# MCXN947_cm33_core0 register map
Vendor: nxp.com; File version: 1.0
CPU: CM33 r2p0, little endian, MPU, FPU, VTOR, 3 interrupt priority bits
Registers are 32-bit, read-write, reset 0x0 unless marked. A register's access mark holds for its fields unless they carry their own. Offsets are from the block's base; [hi:lo] are bit positions; {n}, {i} and the like mark numbered series.

## TRNG0
Base 0x4005A000
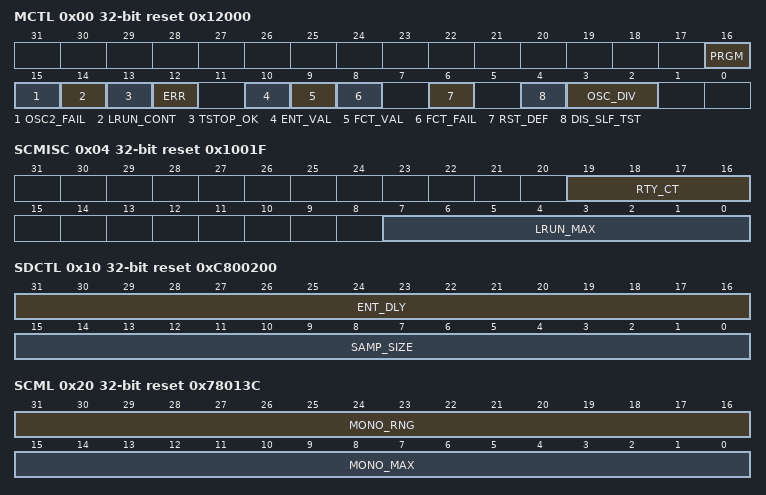
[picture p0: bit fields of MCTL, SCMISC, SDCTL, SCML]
0x00 MCTL reset 0x12000 — Miscellaneous Control Register
  [16] PRGM — Program Mode
    0=DISABLE (TRNG is in Run Mode); 1=ENABLE (TRNG is in Program Mode)
  [15] OSC2_FAIL ro — Oscillator 2 Failure
    0=DISABLE (Oscillator 2 is running.); 1=ENABLE (Oscillator 2 has failed (see OSC2_CTL[OSC_FAILSAFE_LMT]).)
  [14] LRUN_CONT — Long run count continues between entropy generations
    0=DISABLE (The internal test's long run count is restarted for each entropy re-generation.); 1=ENABLE (The count value (of TRNG's internal long_run test), at the start of an entropy generation will continue where it left off at the end of the previous entropy generation.)
  [13] TSTOP_OK ro — TRNG is ok to stop
    0=DISABLE (TRNG is generating entropy and is not ok to stop); 1=ENABLE (TRNG is not generating entropy and is ok to stop)
  [12] ERR write-1-clears — Error Status
    0=DISABLE (No error); 1=ENABLE (Error detected)
  [10] ENT_VAL ro — Entropy Valid
    0=DISABLE (Entropy is not valid); 1=ENABLE (Entropy is valid)
  [9] FCT_VAL ro — Frequency Count Valid
    0=DISABLE (Frequency Count is not valid); 1=ENABLE (Frequency Count is valid)
  [8] FCT_FAIL ro — Frequency Count Fail
  [6] RST_DEF wo — Reset Defaults
    0=DISABLE (No impact.); 1=ENABLE (Writing a 1 to this bit clears various TRNG registers, and bits within registers, to their default state.)
  [4] DIS_SLF_TST wo — Disable Self-Tests
  [3:2] OSC_DIV — Oscillator1 Divide
    0=OSC_DIV_DIV1 (use ring oscillator with no divide); 1=OSC_DIV_DIV2 (use ring oscillator divided-by-2); 2=OSC_DIV_DIV4 (use ring oscillator divided-by-4); 3=OSC_DIV_DIV8 (use ring oscillator divided-by-8)
0x04 SCMISC reset 0x1001F — Statistical Check Miscellaneous Register
  [19:16] RTY_CT — Retry count
  [7:0] LRUN_MAX — Long run max limit
0x10 SDCTL reset 0xC800200 — Seed Control Register
  [31:16] ENT_DLY — Entropy Delay
  [15:0] SAMP_SIZE — Sample Size
0x18 FRQMIN reset 0x1388 (MIN_CNT view) — Frequency Count Minimum Limit Register
  [21:0] FRQ_MIN — Frequency Count Minimum Limit
0x18 OSC2_FRQCNT ro (MIN_CNT view) — Oscillator-2 Frequency Count Register
  [21:0] OSC2_FRQ_CT — Frequency Count
0x1C FRQCNT ro (MAX_CNT view) — Frequency Count Register
  [21:0] FRQ_CT — Frequency Count
0x1C FRQMAX reset 0x61A8 (MAX_CNT view) — Frequency Count Maximum Limit Register
  [21:0] FRQ_MAX — Frequency Counter Maximum Limit
0x20 SCMC ro (SCML_MC view) — Statistical Check Monobit Count Register
  [15:0] MONO_CT — Monobit Count
0x20 SCML reset 0x78013C (SCML_MC view) — Statistical Check Monobit Limit Register
  [31:16] MONO_RNG — Monobit Range
  [15:0] MONO_MAX — Monobit Maximum Limit
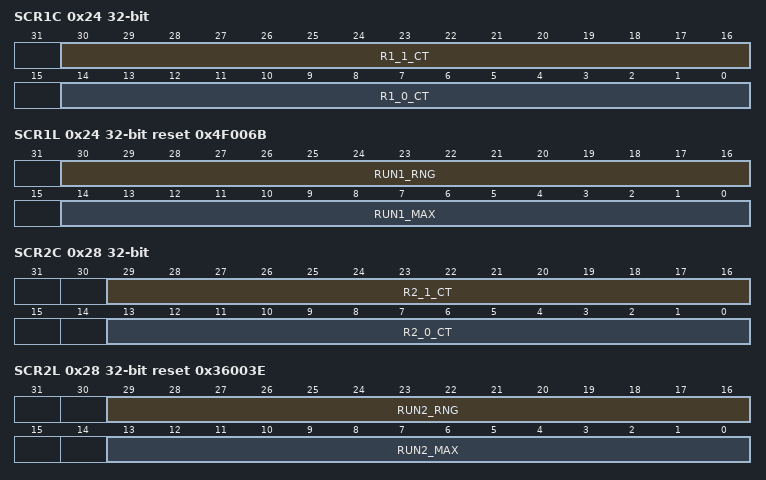
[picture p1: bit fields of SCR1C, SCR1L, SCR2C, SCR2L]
0x24 SCR1C ro (SCR1L_1C view) — Statistical Check Run Length 1 Count Register
  [30:16] R1_1_CT — Runs of One, Length 1 Count
  [14:0] R1_0_CT — Runs of Zero, Length 1 Count
0x24 SCR1L reset 0x4F006B (SCR1L_1C view) — Statistical Check Run Length 1 Limit Register
  [30:16] RUN1_RNG — Run Length 1 Range
  [14:0] RUN1_MAX — Run Length 1 Maximum Limit
0x28 SCR2C ro (SCR2L_2C view) — Statistical Check Run Length 2 Count Register
  [29:16] R2_1_CT — Runs of One, Length 2 Count
  [13:0] R2_0_CT — Runs of Zero, Length 2 Count
0x28 SCR2L reset 0x36003E (SCR2L_2C view) — Statistical Check Run Length 2 Limit Register
  [29:16] RUN2_RNG — Run Length 2 Range
  [13:0] RUN2_MAX — Run Length 2 Maximum Limit
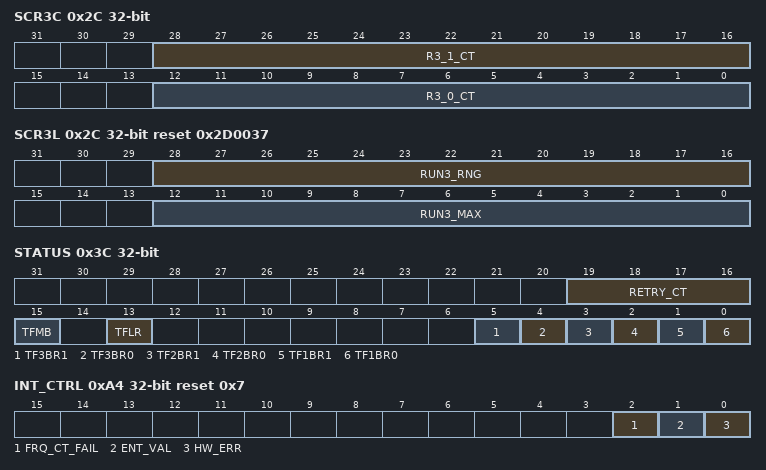
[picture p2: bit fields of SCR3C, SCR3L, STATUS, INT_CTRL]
0x2C SCR3C ro (SCR3L_3C view) — Statistical Check Run Length 3 Count Register
  [28:16] R3_1_CT — Runs of Ones, Length 3 Count
  [12:0] R3_0_CT — Runs of Zeroes, Length 3 Count
0x2C SCR3L reset 0x2D0037 (SCR3L_3C view) — Statistical Check Run Length 3 Limit Register
  [28:16] RUN3_RNG — Run Length 3 Range
  [12:0] RUN3_MAX — Run Length 3 Maximum Limit
0x3C STATUS ro
  [19:16] RETRY_CT — RETRY COUNT
  [15] TFMB — Test Fail, Mono Bit.
    0=DISABLE (The Mono Bit Test has passed); 1=ENABLE (The Mono Bit Test has failed)
  [13] TFLR — Test Fail, Long Run.
    0=DISABLE (The Long Run Test has passed); 1=ENABLE (The Long Run Test has failed)
  [5] TF3BR1 — Test Fail
    0=DISABLE (The 3-Bit Run, Sampling 1s Test has passed); 1=ENABLE (The 3-Bit Run, Sampling 1s Test has failed)
  [4] TF3BR0 — Test Fail, 3-Bit Run, Sampling 0s.
    0=DISABLE (The 3-Bit Run, Sampling 0s Test has passed); 1=ENABLE (The 3-Bit Run, Sampling 0s Test has failed)
  [3] TF2BR1 — Test Fail, 2-Bit Run, Sampling 1s.
    0=DISABLE (The 2-Bit Run, Sampling 1s Test has passed); 1=ENABLE (The 2-Bit Run, Sampling 1s Test has failed)
  [2] TF2BR0 — Test Fail, 2-Bit Run, Sampling 0s.
    0=DISABLE (The 2-Bit Run, Sampling 0s Test has passed); 1=ENABLE (The 2-Bit Run, Sampling 0s Test has failed)
  [1] TF1BR1 — Test Fail, 1-Bit Run, Sampling 1s.
    0=DISABLE (The 1-Bit Run, Sampling 1s Test has passed); 1=ENABLE (The 1-Bit Run, Sampling 1s Test has failed)
  [0] TF1BR0 — Test Fail, 1-Bit Run, Sampling 0s.
    0=DISABLE (The 1-Bit Run, Sampling 0s Test has passed); 1=ENABLE (The 1-Bit Run, Sampling 0s Test has failed)
{0x40+4i} ENT[{i}] (i=0..7) ro — Entropy Read Register
  [31:0] ENT — Entropy Value
0xA0 SEC_CFG — Security Configuration Register
  [1] NO_PRGM — If set, below mentioned TRNG configuration registers cannot be programmed: Oscillator 2 Control Register (OSC2_CTL): TRNG Entropy Generation Control [1:0] Oscillator 2 Divider [3:2] Oscillator Fail Safe Limit [13:12] Oscillator Fail Safe Test [14] TRNG Seed Control Register (SDCTL) TRNG Frequency Count Minimum Limit Register (FRQMIN) TRNG Frequency Count Maximum Limit Register (FRQMAX) TRNG Statistical Check Monobit Limit Register (SCML) TRNG Statistical Check Run Length 1 Limit Register (SCR1L) TRNG Statistical Check Run Length 2 Limit Register (SCR2L) TRNG Statistical Check Run Length 3 Limit Register (SCR3L) TRNG Miscellaneous Control Register (MCTL): Sample Mode [1:0] Oscillator Divider [3:2] Reset Defaults [6] Force System Clock [7] Long Runs Continuation Mode [14] After this bit has been written to a 1, it cannot be changed
    0=NO_PRGM_OFF (TRNG configuration registers can be modified.); 1=NO_PRGM_ON (TRNG configuration registers cannot be modified.)
0xA4 INT_CTRL reset 0x7 — Interrupt Control Register
  [2] FRQ_CT_FAIL — Clear the FRQ_CT_FAIL interrupt.
    0=FRQ_CT_FAIL_CLEAR (Clears the INT_STATUS[FRQ_CT_FAIL] bit. Will automatically set after writing.); 1=FRQ_CT_FAIL_ON (Enables the INT_STATUS[FRQ_CT_FAIL] bit to be set, thereby enabling interrupt generation for the FRQ_CT_FAIL condition.)
  [1] ENT_VAL — Clear the ENT_VAL interrupt.
    0=ENT_VAL_CLEAR (Clears the INT_STATUS[ENT_VAL] bit. Will automatically set after writing.); 1=ENT_VAL_ON (Enables the INT_STATUS[ENT_VAL] bit to be set, thereby enabling interrupt generation for the ENT_VAL condition.)
  [0] HW_ERR — Clear the HW_ERR interrupt.
    0=HW_ERR_CLEAR (Clears the INT_STATUS[HW_ERR] bit. Will automatically set after writing.); 1=HW_ERR_ON (Enables the INT_STATUS[HW_ERR] bit to be set, thereby enabling interrupt generation for the HW_ERR condition.)
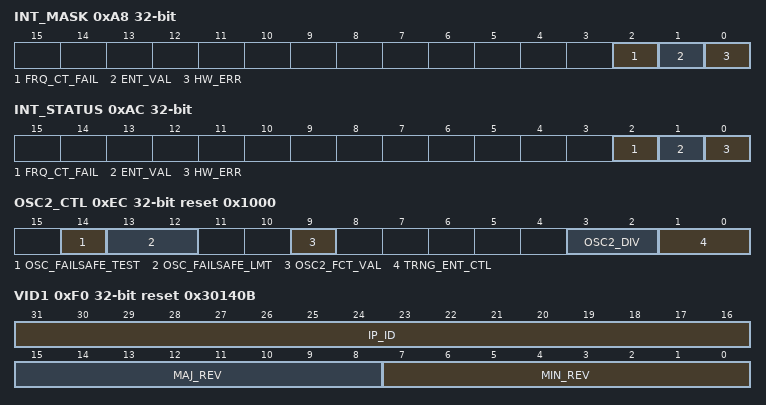
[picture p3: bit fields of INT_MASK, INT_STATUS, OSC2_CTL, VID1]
0xA8 INT_MASK — Mask Register
  [2] FRQ_CT_FAIL — Mask the FRQ_CT_FAIL interrupt.
    0=FRQ_CT_FAIL_MASKED (FRQ_CT_FAIL interrupt is disabled.); 1=FRQ_CT_FAIL_ACTIVE (FRQ_CT_FAIL interrupt is enabled.)
  [1] ENT_VAL — Mask the ENT_VAL interrupt.
    0=ENT_VAL_MASKED (ENT_VAL interrupt is disabled.); 1=ENT_VAL_ACTIVE (ENT_VAL interrupt is enabled.)
  [0] HW_ERR — Mask the HW_ERR interrupt.
    0=HW_ERR_MASKED (HW_ERR interrupt is disabled.); 1=HW_ERR_ACTIVE (HW_ERR interrupt is enabled.)
0xAC INT_STATUS ro — Interrupt Status Register
  [2] FRQ_CT_FAIL — Frequency Count Fail
    0=FRQ_CT_FAIL_NO_ERR (No hardware nor self test frequency errors.); 1=FRQ_CT_FAIL_ERR (The frequency counter has detected a failure.)
  [1] ENT_VAL — Entropy Valid
    0=ENT_VAL_INVALID (Busy generating entropy. Any value read from the Entropy registers is invalid.); 1=ENT_VAL_VALID (Values read from the Entropy registers are valid.)
  [0] HW_ERR — Read: TRNG Error. Any error in the TRNG will trigger this interrupt.
    0=HW_ERR_NO (No error.); 1=HW_ERR_YES (Error detected.)
0xB0 CSER ro — Common Security Error Register
  [1] RED_FSM — Redundant FSM error/fault detected
    0=RED_FSM_NOERR (No redundant FSM error/fault); 1=RED_FSM_ERR (Redundant FSM error/fault detected.)
0xB4 CSCLR wo — Common Security Clear Register
  [1] RED_FSM_CLR — Read only: Redundant FSM error/fault detected
    0=RED_FSM_NOEFFECT (No effect, ignored); 1=RED_FSM_CLEAR (Clears the CSER[RED_FSM] bit.)
0xEC OSC2_CTL reset 0x1000 — TRNG Oscillator 2 Control Register
  [14] OSC_FAILSAFE_TEST — Oscillator fail safe test.
    0=DISABLE (No impact.); 1=ENABLE (Disables oscillator 2 while in dual-oscillator mode (TRNG_ENT_CTL = 01b).)
  [13:12] OSC_FAILSAFE_LMT — Oscillator fail safe limit.
    0=OSC_FAILSAFE_LMT_4K (The limit N is 4096 (2^12) system clocks.); 1=OSC_FAILSAFE_LMT_64K (The limit N is 65536 (2^16) system clocks. (default)); 2=OSC_FAILSAFE_LMT_1M (N is 2^20 system clocks.); 3=OSC_FAILSAFE_LMT_4M (N is 2^22 system clocks (full range of the counter being used).)
  [9] OSC2_FCT_VAL ro — TRNG Oscillator 2 Frequency Count Valid
    0=DISABLE (Frequency count is invalid.); 1=ENABLE (If TRNG_ENT_CTL = 10b, valid frequency count may be read from OSC2_FRQCNT.)
  [3:2] OSC2_DIV — Oscillator 2 Divide.
    0=OSC2_DIV_DIV1 (Use ring oscillator 2 with no divide); 1=OSC2_DIV_DIV2 (Use ring oscillator 2 divided-by-2); 2=OSC2_DIV_DIV4 (Use ring oscillator 2 divided-by-4); 3=OSC2_DIV_DIV8 (Use ring oscillator 2 divided-by-8)
  [1:0] TRNG_ENT_CTL — TRNG entropy generation control.
    0=TRNG_ENT_CTL_SINGLE_OSC1 (Single oscillator mode, using OSC1 (default)); 1=TRNG_ENT_CTL_DUAL_OSCS (Dual oscillator mode); 2=TRNG_ENT_CTL_SINGLE_OSC2 (Single oscillator mode, using OSC2); 3=OSC2_DIV_DIV8 (Unused, (bit field cannot be written to this value))
0xF0 VID1 ro reset 0x30140B — Version ID Register (MS)
  [31:16] IP_ID — Shows the IP ID.
    48=IP_ID_VAL (ID for TRNG.)
  [15:8] MAJ_REV — Shows the IP's Major revision of the TRNG
    20=MAJ_REV_VAL (Major revision number for TRNG.)
  [7:0] MIN_REV — Shows the IP's Minor revision of the TRNG.
    11=MIN_REV_VAL (Minor revision number for TRNG.)
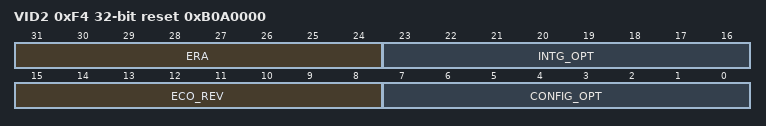
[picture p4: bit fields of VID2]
0xF4 VID2 ro reset 0xB0A0000 — Version ID Register (LS)
  [31:24] ERA — Shows the ERA of the TRNG.
    11=ERA_VAL (ERA of the TRNG.)
  [23:16] INTG_OPT — Shows the integration options for the TRNG.
    10=INTG_OPT_VAL (INTG_OPT for TRNG.)
  [15:8] ECO_REV — Shows the IP's ECO revision of the TRNG.
    0=ECO_REV_VAL (TRNG_ECO_REV for TRNG.)
  [7:0] CONFIG_OPT — Shows the IP's Configuaration options for the TRNG.
    0=CONFIG_OPT_VAL (TRNG_CONFIG_OPT for TRNG.)
